# ATmega169PA register map
Vendor: Atmel; File version: 1.0
CPU: other r0p0, little endian, no MPU, no FPU, 4 interrupt priority bits
Registers are 8-bit, read-write, reset 0x0 unless marked. A register's access mark holds for its fields unless they carry their own. Offsets are from the block's base; [hi:lo] are bit positions; {n}, {i} and the like mark numbered series.

## BOOT_LOAD — Bootloader
Base 0x00000057
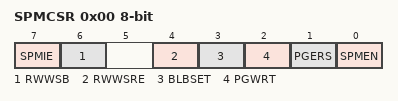
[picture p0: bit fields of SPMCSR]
0x00 SPMCSR — Store Program Memory Control Register
  [7] SPMIE — SPM Interrupt Enable
  [6] RWWSB — Read While Write Section Busy
  [4] RWWSRE — Read While Write section read enable
  [3] BLBSET — Boot Lock Bit Set
  [2] PGWRT — Page Write
  [1] PGERS — Page Erase
  [0] SPMEN — Store Program Memory Enable

## CPU — CPU Registers
Base 0x0000003E
0x00 GPIOR0 — General Purpose IO Register 0
0x0C GPIOR1 — General Purpose IO Register 1
0x0D GPIOR2 — General Purpose IO Register 2
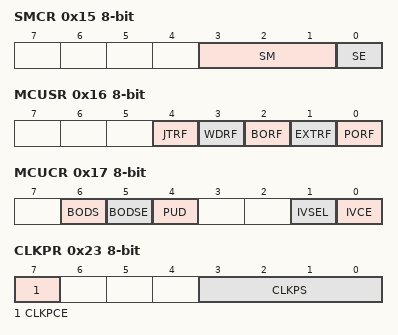
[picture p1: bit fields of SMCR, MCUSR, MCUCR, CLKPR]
0x15 SMCR — Sleep Mode Control Register
  [3:1] SM — Sleep Mode Select bits
    0=IDLE; 1=ADC (ADC Noise Reduction (If Available)); 2=PDOWN (Power Down); 3=PSAVE (Power Save); 6=STDBY (Standby)
  [0] SE — Sleep Enable
0x16 MCUSR — MCU Status Register
  [4] JTRF — JTAG Reset Flag
  [3] WDRF — Watchdog Reset Flag
  [2] BORF — Brown-out Reset Flag
  [1] EXTRF — External Reset Flag
  [0] PORF — Power-on reset flag
0x17 MCUCR — MCU Control Register
  [6] BODS — BOD Sleep
  [5] BODSE — BOD Sleep Enable
  [4] PUD — Pull-up disable
  [1] IVSEL — Interrupt Vector Select
  [0] IVCE — Interrupt Vector Change Enable
0x23 CLKPR — Clock Prescale Register
  [7] CLKPCE — Clock Prescaler Change Enable
  [3:0] CLKPS — Clock Prescaler Select Bits
    0=1; 1=2; 2=4; 3=8; 4=16; 5=32; 6=64; 7=128; 8=256
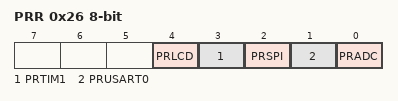
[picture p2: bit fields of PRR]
0x26 PRR — Power Reduction Register
  [4] PRLCD — Power Reduction LCD
  [3] PRTIM1 — Power Reduction Timer/Counter1
  [2] PRSPI — Power Reduction Serial Peripheral Interface
  [1] PRUSART0 — Power Reduction USART
  [0] PRADC — Power Reduction ADC
0x28 OSCCAL — Oscillator Calibration Value
  [7:0] OSCCAL — Oscillator Calibration

## EEPROM
Base 0x0000003F
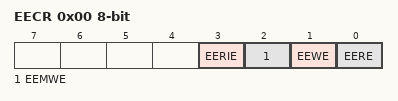
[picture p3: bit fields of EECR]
0x00 EECR — EEPROM Control Register
  [3] EERIE — EEPROM Ready Interrupt Enable
  [2] EEMWE — EEPROM Master Write Enable
  [1] EEWE — EEPROM Write Enable
  [0] EERE — EEPROM Read Enable
0x01 EEDR — EEPROM Data Register
  [7:0] EEDR — EEPROM Data Bits
0x02 EEAR 16-bit (reset mask 0xFF) — EEPROM Address Register Bytes
  [8:0] EEAR — EEPROM Address Bits

## EXINT — External Interrupts
Base 0x0000003C
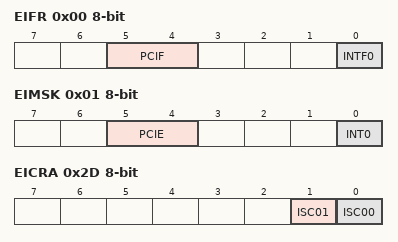
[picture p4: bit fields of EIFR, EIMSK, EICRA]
0x00 EIFR — External Interrupt Flag Register
  [5:4] PCIF — Pin Change Interrupt Flags
  [0] INTF0 — External Interrupt Flag 0
0x01 EIMSK — External Interrupt Mask Register
  [5:4] PCIE — Pin Change Interrupt Enables
  [0] INT0 — External Interrupt Request 0 Enable
0x2D EICRA — External Interrupt Control Register
  [1] ISC01 — External Interrupt Sense Control 0 Bit 1
  [0] ISC00 — External Interrupt Sense Control 0 Bit 0
    0=Low Level of INTX; 1=Any Logical Change of INTX
0x2F PCMSK0 — Pin Change Mask Register 0
  [7:0] PCINT — Pin Change Enable Masks
0x30 PCMSK1 — Pin Change Mask Register 1
  [7:0] PCINT — Pin Change Enable Masks

## JTAG — JTAG Interface
Base 0x00000051
0x00 OCDR — On-Chip Debug Related Register in I/O Memory
0x03 MCUSR — MCU Status Register
  [4] JTRF — JTAG Reset Flag
0x04 MCUCR — MCU Control Register
  [7] JTD — JTAG Interface Disable

## LCD — Liquid Crystal Display
Base 0x000000E4
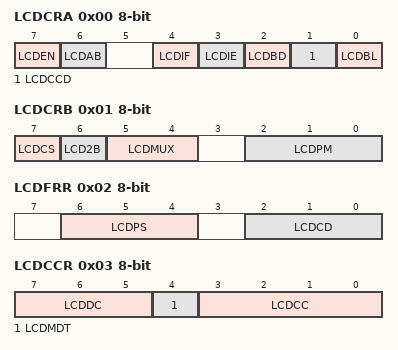
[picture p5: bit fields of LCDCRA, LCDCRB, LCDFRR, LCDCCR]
0x00 LCDCRA — LCD Control Register A
  [7] LCDEN — LCD Enable
  [6] LCDAB — LCD A or B waveform
  [4] LCDIF — LCD Interrupt Flag
  [3] LCDIE — LCD Interrupt Enable
  [2] LCDBD — LCD Buffer Disable
  [1] LCDCCD — LCD Contrast Control Disable
  [0] LCDBL — LCD Blanking
0x01 LCDCRB — LCD Control and Status Register B
  [7] LCDCS — LCD CLock Select
  [6] LCD2B — LCD 1/2 Bias Select
  [5:4] LCDMUX — LCD Mux Selects
  [2:0] LCDPM — LCD Port Masks
    0=SEG0:12; 1=SEG0:14; 2=SEG0:15; 3=SEG0:18; 4=SEG0:20; 5=SEG0:22; 6=SEG0:23; 7=SEG0:24
0x02 LCDFRR — LCD Frame Rate Register
  [6:4] LCDPS — LCD Prescaler Selects
    0=ClkLCD/16; 1=ClkLCD/64; 2=ClkLCD/128; 3=ClkLCD/256; 4=ClkLCD/512; 5=ClkLCD/1024; 6=ClkLCD/2048; 7=ClkLCD/4096
  [2:0] LCDCD — LCD Clock Dividers
    {v}={v+1} (v=0..7)
0x03 LCDCCR — LCD Contrast Control Register
  [7:5] LCDDC — LCD Display Configuration Bits
    0=300us; 1=70us; 2=150us; 3=450us; 4=575us; 5=850us; 6=1150us; 7=50% of LCD clock
  [4] LCDMDT — LCD Maximum Drive Time
  [3:0] LCDCC — LCD Contrast Controls
    0=2.60V; 1=2.65V; 2=2.70V; 3=2.75V; 4=2.80V; 5=2.85V; 6=2.90V; 7=2.95V; 8=3.00V; 9=3.05V; 10=3.10V; 11=3.15V; 12=3.20V; 13=3.25V; 14=3.30V; 15=3.35V
{0x8+i} LCDDR{i} (i=0..3) — LCD Data Register {i}
{0x8+i} LCDDR{i} (i=5..8) — LCD Data Register {i}
{0x8+i} LCDDR{i} (i=10..13) — LCD Data Register {i}
{0x8+i} LCDDR{i} (i=15..18) — LCD Data Register {i}
